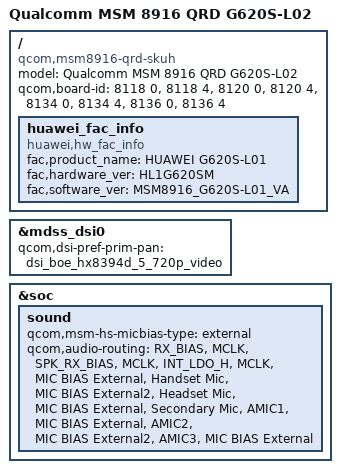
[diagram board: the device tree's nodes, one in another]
/* Copyright (c) 2014, The Linux Foundation. All rights reserved.
 *
 * This program is free software; you can redistribute it and/or modify
 * it under the terms of the GNU General Public License version 2 and
 * only version 2 as published by the Free Software Foundation.
 *
 * This program is distributed in the hope that it will be useful,
 * but WITHOUT ANY WARRANTY; without even the implied warranty of
 * MERCHANTABILITY or FITNESS FOR A PARTICULAR PURPOSE.  See the
 * GNU General Public License for more details.
 */

/dts-v1/;

#include "msm8916-qrd.dtsi"
#include "msm8916-memory.dtsi"
#include "c8817d/msm8916-qrd-c8817d.dtsi"

/ {
	model = "Qualcomm MSM 8916 QRD G620S-L02";
	compatible = "qcom,msm8916-qrd-skuh", "qcom,msm8916-qrd", "qcom,msm8916", "qcom,qrd";
	qcom,board-id = <8118 0>, <8118 4>,
			<8120 0>, <8120 4>,
			<8134 0>, <8134 4>,
			<8136 0>, <8136 4>;
};

&mdss_dsi0 {
	qcom,dsi-pref-prim-pan = <&dsi_boe_hx8394d_5_720p_video>;
};

&soc {

	sound {
		qcom,msm-hs-micbias-type = "external";
		qcom,audio-routing =
				"RX_BIAS", "MCLK",
				"SPK_RX_BIAS", "MCLK",
				"INT_LDO_H", "MCLK",
				"MIC BIAS External", "Handset Mic",
				"MIC BIAS External2", "Headset Mic",
				"MIC BIAS External", "Secondary Mic",
				"AMIC1", "MIC BIAS External",
				"AMIC2", "MIC BIAS External2",
				"AMIC3", "MIC BIAS External";
	};
};

/ {
	huawei_fac_info {
		compatible = "huawei,hw_fac_info";
		fac,product_name = "HUAWEI G620S-L01";
		fac,hardware_ver = "HL1G620SM";
		fac,software_ver = "MSM8916_G620S-L01_VA";
		status = "ok";
	};
};
